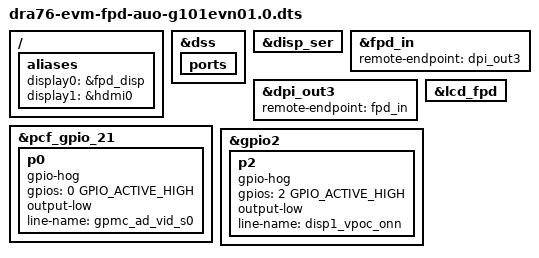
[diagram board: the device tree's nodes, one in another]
#include "dra76-evm.dts"
#include "dra7x-evm-fpd-auo-g101evn01.0.dtsi"

/ {
	aliases {
		display0 = &fpd_disp;
		display1 = &hdmi0;
	};
};

&dss {
	ports {
		status = "ok";
	};
};

&disp_ser {
	status = "ok";
	ranges = <0x0 0x2d>;
};

/* Tie the end points of DSS and FPDLink together */
&fpd_in {
	remote-endpoint = <&dpi_out3>;
};

&dpi_out3 {
	remote-endpoint = <&fpd_in>;
};

&lcd_fpd {
	status = "ok";
};

/* U21 on the EVM */
/* gpmc_ad_vid_s0: high: GPMC , low: VOUT3 */
&pcf_gpio_21 {
	p0 {
		gpio-hog;
		gpios = <0 GPIO_ACTIVE_HIGH>;
		output-low;
		line-name = "gpmc_ad_vid_s0";
	};
};


/* U110 on the EVM. For Rev A boards */
/*
&pcf_hdmi {
	p11 {
		gpio-hog;
		gpios = <11 GPIO_ACTIVE_HIGH>;
		output-low;
		line-name = "disp1_vpoc_onn";
	};
};
*/

/* For supplying power to the display via FPDLink */
&gpio2 {
	p2 {
		gpio-hog;
		gpios =  <2 GPIO_ACTIVE_HIGH>;
		output-low;
		line-name = "disp1_vpoc_onn";
	};
};
